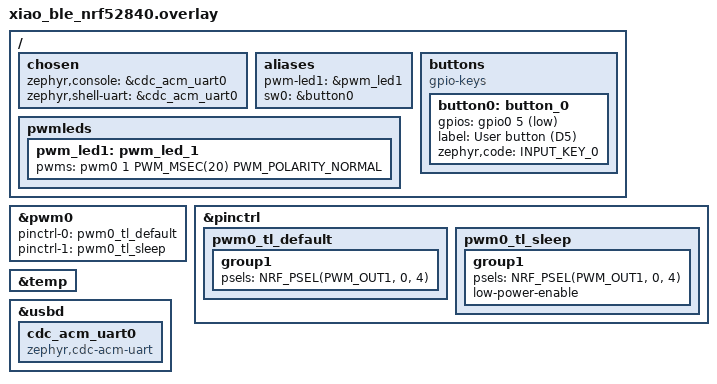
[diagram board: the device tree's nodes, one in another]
#include <zephyr/dt-bindings/input/input-event-codes.h>
/* XIAO nRF52840 (xiao_ble) overlay for the Matter light bulb.
 * PWM light on P0.04 = XIAO D4 (same pin as the tea light). Console on the
 * nRF52840's own USB CDC ACM, since the board has no debug probe. */
/ {
	chosen {
		zephyr,console = &cdc_acm_uart0;
		zephyr,shell-uart = &cdc_acm_uart0;
	};
	aliases {
		pwm-led1 = &pwm_led1;
	};
	pwmleds {
		pwm_led1: pwm_led_1 {
			pwms = <&pwm0 1 PWM_MSEC(20) PWM_POLARITY_NORMAL>;
		};
	};
};
&pwm0 {
	status = "okay";
	pinctrl-0 = <&pwm0_tl_default>;
	pinctrl-1 = <&pwm0_tl_sleep>;
	pinctrl-names = "default", "sleep";
};
&pinctrl {
	pwm0_tl_default: pwm0_tl_default { group1 { psels = <NRF_PSEL(PWM_OUT1, 0, 4)>; }; };
	pwm0_tl_sleep:   pwm0_tl_sleep   { group1 { psels = <NRF_PSEL(PWM_OUT1, 0, 4)>; low-power-enable; }; };
};
&temp { status = "okay"; };
zephyr_udc0: &usbd {
	status = "okay";
	cdc_acm_uart0: cdc_acm_uart0 {
		compatible = "zephyr,cdc-acm-uart";
	};
};

/* Nordic's Matter board glue iterates a `buttons` node; the XIAO has no user
 * button, so define one on D5 = P0.05 (active low, internal pull-up). Left
 * unconnected it simply never presses. Long-press = factory reset in the sample. */
/ {
	buttons {
		compatible = "gpio-keys";
		button0: button_0 {
			gpios = <&gpio0 5 (GPIO_PULL_UP | GPIO_ACTIVE_LOW)>;
			label = "User button (D5)";
			zephyr,code = <INPUT_KEY_0>;
		};
	};
	aliases {
		sw0 = &button0;
	};
};
